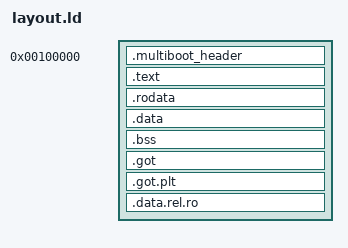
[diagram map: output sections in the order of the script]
ENTRY(start)

SECTIONS {
    . = 1M;

    .multiboot_header :
    {
        /* ensure that the multiboot header is at the beginning */
        KEEP(*(.multiboot_header))
        . = ALIGN(4K);
    }

    .text :
    {
        *(.text .text.*)
        . = ALIGN(4K);
    }

    .rodata : {
        *(.rodata .rodata.*)
        . = ALIGN(4K);
    }

    .data :
    {
        *(.data .data.*)
        . = ALIGN(4K);
    }

    .bss :
    {
        *(.bss .bss.*)
        . = ALIGN(4K);
    }

    .got :
    {
        *(.got)
        . = ALIGN(4K);
    }

    .got.plt :
    {
        *(.got.plt)
        . = ALIGN(4K);
    }

    .data.rel.ro : ALIGN(4K) {
        *(.data.rel.ro.local*) *(.data.rel.ro .data.rel.ro.*)
        . = ALIGN(4K);
    }


}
